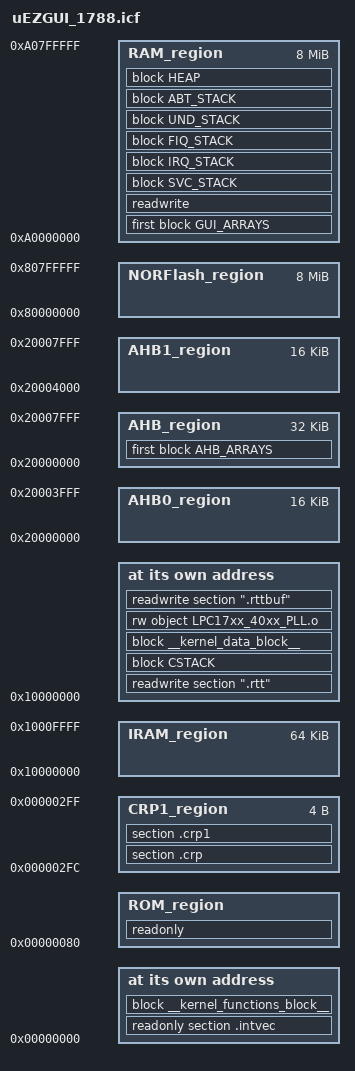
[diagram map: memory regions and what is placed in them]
/*###ICF### Section handled by ICF editor, don't touch! ****/
/*-Editor annotation file-*/

/*-Specials-*/
define symbol __ICFEDIT_intvec_start__ = 0x00000000;

/*-Memory Regions-*/
define symbol __ICFEDIT_region_ROM_start__ = 0x00000080;
define symbol __ICFEDIT_region_ROM_end__   = 0x0007FFFF;
define symbol __ICFEDIT_region_RAM_start__ = 0xA0000000;
define symbol __ICFEDIT_region_RAM_end__   = 0xA07FFFFF;

/*-Sizes-*/
define symbol __ICFEDIT_size_cstack__   = 0x400;
define symbol __ICFEDIT_size_svcstack__ = 0x10;
define symbol __ICFEDIT_size_irqstack__ = 0x100;
define symbol __ICFEDIT_size_fiqstack__ = 0x100;
define symbol __ICFEDIT_size_undstack__ = 0x10;
define symbol __ICFEDIT_size_abtstack__ = 0x10;
define symbol __ICFEDIT_size_heap__     = 900000;
/**** End of ICF editor section. ###ICF###*/

/*-- uEZ Defines: -----------------------------------------------------------*/
/* USe the SRAM for the system stack and the kernel data. */
define symbol IRAM_start        = 0x10000000;
define symbol IRAM_end          = 0x1000FFFF;
define symbol NORFlash_start    = 0x80000000;
define symbol NORFlash_end      = 0x807FFFFF;
define symbol AHB0_start        = 0x20000000;
define symbol AHB0_end          = 0x20003FFF;
define symbol AHB1_start        = 0x20004000;
define symbol AHB1_end          = 0x20007FFF;

/********* CRP (Code Read Protection) REGION *********/
define symbol __CRP1_start__   = 0x000002FC;
define symbol __CRP1_end__     = 0x000002FF;

/*-- Sizes: -----------------------------------------------------------------*/
/* This must match the number of implemented vectors * 4 and be padded to an 8
byte boundary (check the mapfile to ensure that the kernel function region is 
correctly occupying the first 8K region of flash). There does not seem to be any 
way of dynamically determining the size of the vector table section at link time, 
hence this direct definition. */
define symbol __size_vectors__              = 0xE8;

/*-- Memory and Regions: ----------------------------------------------------*/
define memory mem with size = 4G;
define region ROM_region = mem:[from __ICFEDIT_region_ROM_start__ to __ICFEDIT_region_ROM_end__] - mem:[from  __CRP1_start__ to __CRP1_end__];
define region CRP1_region = mem:[from  __CRP1_start__ to __CRP1_end__];
define region RAM_region = mem:[from __ICFEDIT_region_RAM_start__ to __ICFEDIT_region_RAM_end__];
define region IRAM_region = mem:[from IRAM_start to IRAM_end];
define region NORFlash_region = mem:[from NORFlash_start   to NORFlash_end];
define region AHB0_region = mem:[from AHB0_start to AHB0_end];
define region AHB1_region = mem:[from AHB1_start to AHB1_end];
define region AHB_region = mem:[from AHB0_start to AHB1_end];

/*-- Blocks: ----------------------------------------------------------------*/
define block CSTACK    with alignment = 8, size = __ICFEDIT_size_cstack__   { };
define block SVC_STACK with alignment = 8, size = __ICFEDIT_size_svcstack__ { };
define block IRQ_STACK with alignment = 8, size = __ICFEDIT_size_irqstack__ { };
define block FIQ_STACK with alignment = 8, size = __ICFEDIT_size_fiqstack__ { };
define block UND_STACK with alignment = 8, size = __ICFEDIT_size_undstack__ { };
define block ABT_STACK with alignment = 8, size = __ICFEDIT_size_abtstack__ { };
define block HEAP      with alignment = 8, size = __ICFEDIT_size_heap__     { };

/*-- Placment Commands (General): -------------------------------------------*/
initialize by copy { readwrite };
do not initialize  { section .noinit, section .network };

/* Define a block for the kernel's functions.  - __size_vectors__ because the 
first part of the 8K is taken by the interrupt vectors. */
define block __kernel_functions_block__ with alignment = 8, 
    size = 0x2000 - __size_vectors__ { section __kernel_functions__ };

/* Place the interrupt vectors at the required address, followed by the kernel's
functions. */
place at address mem:__ICFEDIT_intvec_start__ { 
    readonly section .intvec, 
    block __kernel_functions_block__ 
};

/* Define a block for the kernel's data. */
define block __kernel_data_block__ with alignment = 0x400, size = 0x400 { section __kernel_data__ };

/* Place the main stack at the start of IRAM, followed by the kernel's data. */
place at address mem:IRAM_start  { 
    readwrite section ".rtt", /*SEGGER_RTT_SECTION*/
    block CSTACK, 
    block __kernel_data_block__, 
    rw object LPC17xx_40xx_PLL.o, 
    readwrite section ".rttbuf", /*SEGGER_RTT_BUFFER_SECTION*/
};

place in ROM_region   { readonly };

/*place in NORFlash_region   { 
    readonly section .ExternalFlashText,
    readonly section .ExternalFlashRodata,
    readonly section .ExternalFlash,
    ro object UDCImages.o,
    ro object GUIDEMO_Resource.o,};*/

/* Place these sections in order at the very beginning of SDRAM */
/* Currently in uEZ it is important that frames is first. */
define block GUI_ARRAYS with fixed order {
    readwrite section ".frames", /*Frames section*/
    readwrite section ".video",
    readwrite section ".emWin", /*emWin section*/
    /*Move rttbuf section here when using systemview with large trace buffer allocation. May break some RAM tests. */
    readwrite section ".network" /*Network section*/
};

place in RAM_region { 
    first block GUI_ARRAYS,
    readwrite,
    block SVC_STACK, 
    block IRQ_STACK, 
    block FIQ_STACK,
    block UND_STACK, 
    block ABT_STACK, 
    block HEAP
};

place in AHB0_region {
    //readwrite section .emacmem,
};

place in AHB1_region {
    //readwrite section .mcimem,
    //readwrite section .usbhostmem,
};

define block AHB_ARRAYS with fixed order {
    readwrite section .usbhostmem,
    readwrite section .mcimem,
    readwrite section .emacmem,
};

place in AHB_region {
    first block AHB_ARRAYS,
};

place in CRP1_region              { section .crp,  section .crp1 };

/*-- Exports: ---------------------------------------------------------------*/
/* Export symbols required by c code. */
export symbol __ICFEDIT_intvec_start__;
export symbol __ICFEDIT_size_cstack__;
export symbol __ICFEDIT_region_ROM_start__;
export symbol __ICFEDIT_region_ROM_end__;

